# WS53 register map
File version: 0.1.0-experimental
Registers are 32-bit, read-write, no defined reset value unless marked. A register's access mark holds for its fields unless they carry their own. Offsets are from the block's base; [hi:lo] are bit positions.

## GPIO1
Base 0x57028000
0x00 GPIO_SW_OUT
  [11:0] GPIO_SW_OUT — GPIO data. Output: written value drives I/O; Input: reads external port
0x04 GPIO_SW_OEN
  [11:0] PINS — Direction bitmap: each 0 bit selects output, each 1 bit selects input; not a whole-register mode enum
0x08 GPIO_SW_CTL
  [11:0] GPIO_SW_CTL — Per-pin data source control; SDK supplies bit get/set helpers but does not establish selection encodings
0x0C GPIO_INT_EN
  [11:0] GPIO_INT_EN — Interrupt enable: 0=normal GPIO; 1=interrupt port
0x10 GPIO_INT_MASK
  [11:0] GPIO_INT_MASK — Interrupt mask: 0=not masked; 1=masked
0x14 GPIO_INT_TYPE
  [11:0] PINS — Trigger bitmap: each 0 bit selects level, each 1 bit selects edge
0x18 GPIO_INT_POLARITY
  [11:0] PINS — Polarity bitmap: each 0 bit selects low/falling, each 1 bit high/rising
0x1C GPIO_INT_DEDGE
  [11:0] PINS — Dual-edge bitmap: each 1 bit enables detection on both edges of that input
0x20 GPIO_INT_DEBOUNCE
  [11:0] GPIO_INT_DEBOUNCE — Debounce enable: 0=disabled; 1=enabled
0x24 GPIO_INT_RAW ro
  [11:0] GPIO_INT_RAW — Raw interrupt status (before mask): 0=no interrupt; 1=interrupt
0x28 GPIO_INTR ro
  [11:0] GPIO_INTR — Interrupt status (after mask): 0=no interrupt; 1=interrupt
0x2C GPIO_INT_EOI wo
  [11:0] GPIO_INT_EOI write-1-clears — Edge interrupt clear: 0=no clear; 1=clear interrupt
0x30 GPIO_DATA_SET wo
  [11:0] GPIO_DATA_SET write-1-sets — Write 1 to set corresponding GPIO_SW_OUT bits
0x34 GPIO_DATA_CLR wo
  [11:0] GPIO_DATA_CLR write-1-clears — Write 1 to clear corresponding GPIO_SW_OUT bits

## RTC0
Base 0x57029100
Same registers: RTC1 0x57029200
0x00 LOAD_COUNT0
0x04 LOAD_COUNT1
0x08 CURRENT_VALUE0 ro
0x0C CURRENT_VALUE1 ro
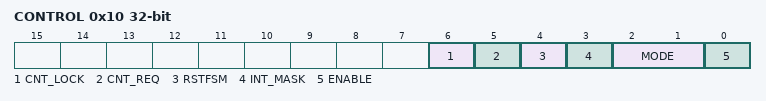
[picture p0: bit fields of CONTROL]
0x10 CONTROL access per field
  [6] CNT_LOCK ro — Snapshot ready status, polled after CNT_REQ; no software setter in SDK
  [5] CNT_REQ rw
  [4] RSTFSM rw
  [3] INT_MASK rw
  [2:1] MODE rw
    0=OneShot (SDK one-shot mode); 1=Periodic (SDK periodic mode); 2=OneShotAlternate (SDK alias of one-shot mode); 3=FreeRun (SDK free-run mode)
  [0] ENABLE rw
0x14 EOI_REN wo
  [0] EOI range 1..1 — SDK acknowledges by writing one. Header claims read-clear but driver never reads; read behavior withheld
0x18 RAW_INTR ro
  [0] INT_STATUS
0x1C INTR ro
  [0] INT_STATUS

## WDT
Base 0x5702B000
0x00 LOCK_STATUS ro
  [0] LOCKED — 0 unlocked, 1 locked; not the last written key
0x00 LOCK_COMMAND wo (alternate view of LOCK_STATUS)
  [31:0] KEY — 0x5A5A5A5A unlocks; any other value locks
0x04 WDT_LOAD
  [31:8] WDT_LOAD — Load count value (24-bit, low 8 bits reserved)
0x08 WDT_RESTART wo
  [31:0] WDT_RESTART range 1515870810..1515870810 — SDK kick writes 0x5A5A5A5A; other keys have contradictory SDK comments and are not specified
0x0C WDT_EOI ro read-has-side-effects
  [0] WDT_EOI read-has-side-effects — Read returns zero and clears interrupt per SDK register comment; SDK clear helper reads then writes 1, independent write-only clear behavior unverified
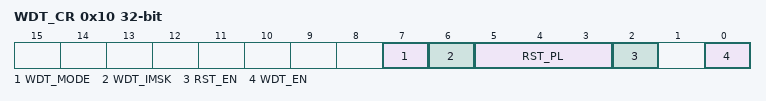
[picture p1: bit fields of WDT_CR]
0x10 WDT_CR
  [7] WDT_MODE — 0 reset on first expiry interrupt, 1 reset on second expiry interrupt; reset still gated by RST_EN
    0=Reset on first expiry interrupt when RST_EN is set; 1=Reset on second expiry interrupt when RST_EN is set
  [6] WDT_IMSK — Interrupt mask: 0=unmasked; 1=masked
  [5:3] RST_PL — Reset pulse length: 000=2 clocks; up to 111=256 clocks
  [2] RST_EN — Reset enable: 0=no reset on timeout; 1=reset on timeout
  [0] WDT_EN — Watchdog enable: 0=disabled; 1=enabled
0x14 WDT_CNT ro read-has-side-effects
  [31:0] WDT_CNT read-has-side-effects — Consume the valid counter snapshot; A-board observation: reading CNT clears CCVR validity. A new request issued too soon after consumption may be lost even when BUSY is zero. Read only once per valid snapshot; rearm latency and command ordering need qualification.
0x18 WDT_RAW_INTR ro
  [0] WDT_RAW_INTR — Raw interrupt status
0x1C WDT_INTR ro
  [0] WDT_INTR — Interrupt status after mask
0x20 WDT_LPIF_STATE ro
  [2:0] WDT_LPIF_STATE — Low power interface state
0x24 WDT_STATUS ro
  [0] WDT_STATUS — SDK register definition: 0 free, 1 busy
0x28 CCVR_STATUS ro
  [1] VALID — Snapshot valid until CNT is consumed; A-board validity remains set when CNT is not read, and clears after its read. BUSY zero does not prove that another request can be accepted.
0x28 CCVR_REQUEST wo (alternate view of CCVR_STATUS)
  [0] REQUEST range 1..1
